# spixfc_reva_me55 register map
Registers are access not given, no defined reset value unless marked. A register's access mark holds for its fields unless they carry their own. Offsets are from the block's base; lines under a group give offsets from that group; [hi:lo] are bit positions; {n}, {i} and the like mark numbered series; 'fields as' and 'values as' point back to an identical list; <NAME> marks a mode.

## Memory map
0x40027000 SPIXFC size 0x1000 — SPI XiP Flash Configuration Controller

## Interrupts
38 SPIXFC — SPIXFC IRQ

## SPIXFC — SPI XiP Flash Configuration Controller
Base 0x40027000
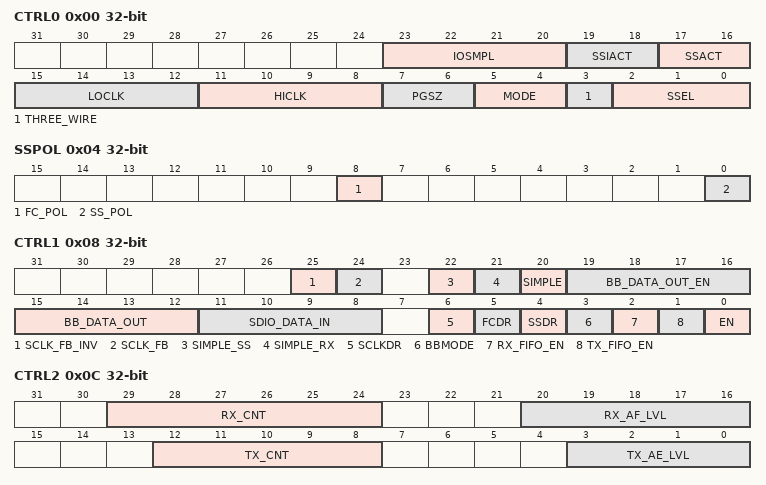
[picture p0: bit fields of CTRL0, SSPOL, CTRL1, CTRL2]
0x00 CTRL0 — Control Register.
  [23:20] IOSMPL — Sample Delay
  [19:18] SSIACT — Slaves Select Inactive Timing.
    0=4_CLKS (4 sytem clocks.); 1=6_CLKS (6 sytem clocks.); 2=8_CLKS (8 sytem clocks.); 3=12_CLKS (12 sytem clocks.)
  [17:16] SSACT — Slaves Select Activate Timing.
    0=0_CLKS (0 sytem clocks.); 1=2_CLKS (2 sytem clocks.); 2=4_CLKS (4 sytem clocks.); 3=8_CLKS (8 sytem clocks.)
  [15:12] LOCLK — SCLK low Clocks. Number of system clocks that SCLK will be low when SCLK pulses are generated. 0 correspond to 16 system clocks and, all other values defines the number of system clock taht SCLK will be held low.
    0=16_SCLK (16 system clocks.)
  [11:8] HICLK — SCLK High Clocks. Number of system clocks that SCLK will be high when SCLK pulses are generated. 0 Correspond to 16 system clocks and, all other values defines the number of system clock taht SCLK will be held high.
    0=16_SCLK (16 system clocks.)
  [7:6] PGSZ — Page Size.
    0=4_bytes; 1=8_bytes; 2=16_bytes; 3=32_bytes
  [5:4] MODE — Defines SPI Mode, Only valid values are 0 and 3.
    0=SPI_Mode_0 (SPIX Mode 0. CLK Polarity = 0, CLK Phase = 0.); 3=SPI_Mode_3 (SPIX Mode 3. CLK Polarity = 1, CLK Phase = 1.)
  [3] THREE_WIRE — Three Wire Mode.
  [2:0] SSEL — Slaves Select.
    0=Slave 0 is selected; 1=Slave 1 is selected
0x04 SSPOL — SPIX Controller Slave Select Polarity Register.
  [8] FC_POL — FC Polarity.
    0=lo (Active Low.); 1=hi (Active High.)
  [0] SS_POL — Slave Select Polarity.
    0=lo (Active Low.); 1=hi (Active High.)
0x08 CTRL1 — SPIX Controller General Controller Register.
  [25] SCLK_FB_INV — SCK Invert.
  [24] SCLK_FB — Enable SCLK Feedback Mode.
    0=Dis; 1=En
  [22] SIMPLE_SS — Simple Mode Slave Select.
  [21] SIMPLE_RX — Simple Receive Enable.
  [20] SIMPLE — Simple Mode Enable.
  [19:16] BB_DATA_OUT_EN — Bit Bang SDIO Output Enable.
    {v}=SDIO{v} (v=0..3)
  [15:12] BB_DATA_OUT
    {v}=SDIO{v} (v=0..3)
  [11:8] SDIO_DATA_IN — SDIO Input Data Value.
    {v}=SDIO{v} (v=0..3)
  [6] SCLKDR — SCLK Drive and State.
    0=SCLK_0 (SCLK is 0.); 1=SCLK_1 (SCLK is 1.)
  [5] FCDR — This bits reflects the state of the selected FC.
  [4] SSDR — This bits reflects the state of the currently selected slave select.
    0=output0 (Selected Slave select output = 0.); 1=output1 (Selected Slave select output = 1.)
  [3] BBMODE — Bit-Bang Mode.
    0=dis (Disable Bit-Bang Mode.); 1=en (Enable Bit-Bang Mode.)
  [2] RX_FIFO_EN — Result FIFO Enable.
    0=DIS_RXFIFO (Disable Result FIFO.); 1=EN_RXFIFO (Enable Result FIFO.)
  [1] TX_FIFO_EN — Transaction FIFO Enable.
    0=dis_txfifo (Disable Transaction FIFO.); 1=en_txfifo (Enable Transaction FIFO.)
  [0] EN — SPI Master enable.
    0=dis (Disable SPI Master, putting a reset state.); 1=en (Enable SPI Master for processing transactions.)
0x0C CTRL2 — SPIX Controller FIFO Control and Status Register.
  [29:24] RX_CNT — Result FIFO Used.
  [20:16] RX_AF_LVL — Results FIFO Almost Full Level.
  [12:8] TX_CNT — Transaction FIFO Used.
  [3:0] TX_AE_LVL — Transaction FIFO Almost Empty Level.
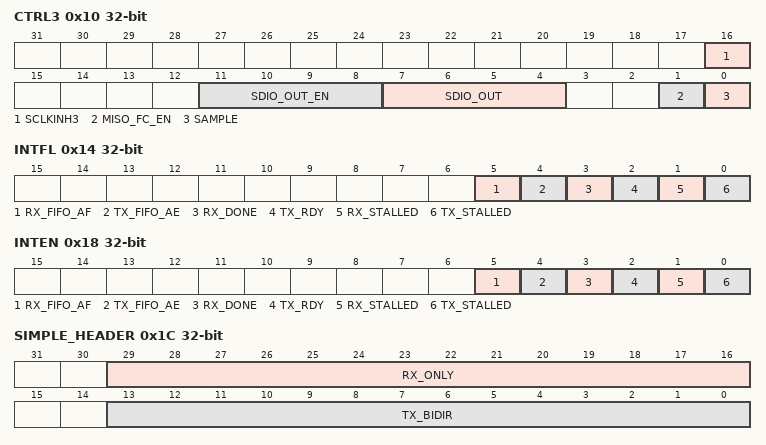
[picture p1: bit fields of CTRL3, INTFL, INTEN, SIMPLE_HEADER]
0x10 CTRL3 — SPIX Controller Special Control Register.
  [16] SCLKINH3 — SCLK Inhibit Mode3. In SPI Mode 3, some SPI flash read timing diagrams show the last SCLK going low prior to de-assertion. The default is to support this additional falling edge of clock. When this bit is set and the device is in SPI Mode 3, the SPI clock is held high while Slave Select is de-asserted. This is to support some SPI flash write timing diagrams.
    0=EN (Allow trailing SCLK low pulse prior to Slave Select de-assertion.); 1=DIS (Inhibit trailing SCLK low pulse prior to Slave Select de-assertion.)
  [11:8] SDIO_OUT_EN — SDIO Output Enable Sample Mode
  [7:4] SDIO_OUT — SDIO Output Value Sample Mode
  [1] MISO_FC_EN — MISO FC Enable.
  [0] SAMPLE — Setting this bit to a 1 enables the ability to drive SDIO outputs prior to the assertion of Slave Select. This bit must only be set when the SPIXF bus is idle and the transaction FIFO is empty. This bit is automatically cleared by hardware after the next slave select assertion.
0x14 INTFL — SPIX Controller Interrupt Status Register.
  [5] RX_FIFO_AF — Results FIFO Almost Full Flag.
    0=CLR (Results FIFO level below the Almost Full level.); 1=SET (Results FIFO level at Almost Full level.)
  [4] TX_FIFO_AE — Transaction FIFO Almost Empty Flag.
    0=CLR (Transaction FIFO not Almost Empty.); 1=SET (Transaction FIFO Almost Empty.)
  [3] RX_DONE — Results Done Interrupt Status.
    0=CLR (Results FIFO ready.); 1=SET (Results FIFO Not ready.)
  [2] TX_RDY — Transaction Ready Interrupt Status.
    0=CLR (FIFO Transaction not ready.); 1=SET (FIFO Transaction ready.)
  [1] RX_STALLED — Results Stalled Interrupt Flag.
    0=CLR (Normal FIFO Operation.); 1=SET (Stalled FIFO.)
  [0] TX_STALLED — Transaction Stalled Interrupt Flag.
    0=CLR (Normal FIFO Transaction.); 1=SET (Stalled FIFO Transaction.)
0x18 INTEN — SPIX Controller Interrupt Enable Register.
  [5] RX_FIFO_AF — Results FIFO Almost Full Interrupt Enable.
    0=EN (Disable Results FIFO Almost Full Interrupt.); 1=DIS (Enable Results FIFO Almost Full Interrupt.)
  [4] TX_FIFO_AE — Transaction FIFO Almost Empty Interrupt Enable.
    0=EN (Disable Transaction FIFO Almost Empty Interrupt.); 1=DIS (Enable Transaction FIFO Almost Empty Interrupt.)
  [3] RX_DONE — Results Done Interrupt Enable.
    0=EN (Disable Results Done Interrupt.); 1=DIS (Enable Results Done Interrupt.)
  [2] TX_RDY — Transaction Ready Interrupt Enable.
    0=EN (Disable FIFO Transaction Ready Interrupt.); 1=DIS (Enable FIFO Transaction Ready Interrupt.)
  [1] RX_STALLED — Results Stalled Interrupt Enable.
    0=EN (Disable Results Stalled Interrupt.); 1=DIS (Enable Results Stalled Interrupt.)
  [0] TX_STALLED — Transaction Stalled Interrupt Enable.
    0=EN (Disable Transaction Stalled Interrupt.); 1=DIS (Enable Transaction Stalled Interrupt.)
0x1C SIMPLE_HEADER
  [29:16] RX_ONLY — RX Only Header.
  [13:0] TX_BIDIR — TX Bdirectional Header.
0x20 AUTOCN — Auto Control Register.
  [31:0] AUTOCN
0x24 AUTOCMD — Auto Command Register.
  [31:0] AUTOCMD
